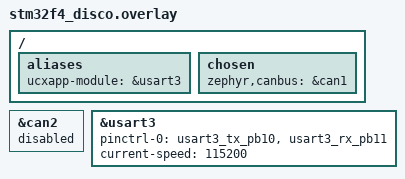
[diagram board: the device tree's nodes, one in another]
/* STM32F4DISCOVERY (same wiring as the FreeRTOS build): module TX -> PB11 (USART3_RX),
 * module RX <- PB10 (USART3_TX). The shell is on USART2 (PA2/PA3, zephyr,console) via a USB-UART adapter. */

/ {
	aliases {
		ucxapp-module = &usart3;
	};
	chosen {
		/* can.* on CAN1, RX PD0, TX PD1, as in the FreeRTOS build; CAN2's PB13 is the SD card clock. */
		zephyr,canbus = &can1;
	};
};

&can2 {
	status = "disabled";
};

&usart3 {
	pinctrl-0 = <&usart3_tx_pb10 &usart3_rx_pb11>;
	pinctrl-names = "default";
	current-speed = <115200>;
	status = "okay";
};
